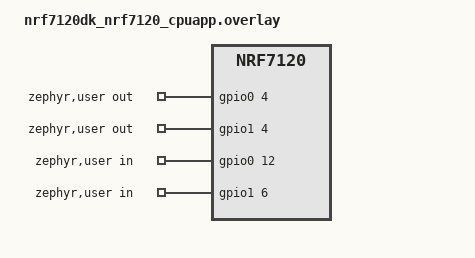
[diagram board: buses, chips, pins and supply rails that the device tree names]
/ {
	/* Test requirements:
	 * out-gpios[0] wire connected with in-gpios[0],
	 * out-gpios[1] wire connected with in-gpios[1],
	 * etc.
	 * Output-input GPIO pair must have identical active level flag.
	 */
	zephyr,user {
		out-gpios = <&gpio0 4 GPIO_ACTIVE_HIGH>, <&gpio1 4 GPIO_ACTIVE_HIGH>;
		in-gpios = <&gpio0 12 GPIO_ACTIVE_HIGH>, <&gpio1 6 GPIO_ACTIVE_HIGH>;
	};
};

&uicr {
	nfct-pins-as-gpios;
};

&gpio0 {
	status = "okay";
};

&gpio1 {
	status = "okay";
};

/* Enable interrupt from GPIO P1 events. */
&gpiote20 {
	status = "okay";
};

/* Enable interrupt from GPIO P0 events. */
&gpiote30 {
	status = "okay";
};
